AUTOSAR XML (schema 00044)
package /ComponentTypes
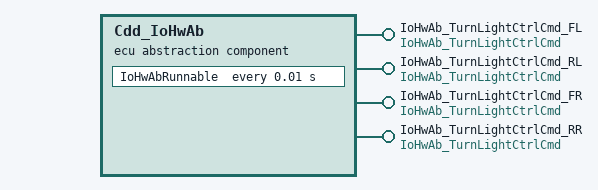
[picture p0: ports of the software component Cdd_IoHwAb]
  ecu abstraction sw component type Cdd_IoHwAb
    4 x provide port, all with server-com-spec{operation=Operation, queue-length=1}, provided-interface=IoHwAb_TurnLightCtrlCmd:
      IoHwAb_TurnLightCtrlCmd_FL
      IoHwAb_TurnLightCtrlCmd_RL
      IoHwAb_TurnLightCtrlCmd_FR
      IoHwAb_TurnLightCtrlCmd_RR
    behavior Cdd_IoHwAb_InternalBehavior
      timing event TMT_IoHwAbRunnable: start-on-event=IoHwAbRunnable, period=0.01
      4 x operation invoked event:
        OIT_Runnable_IoHwAb_TurnLightCtrlCmd_FL_Operation: start-on-event=IoHwAb_TurnLightCtrlCmd_FL_Operation, operation=IoHwAb_TurnLightCtrlCmd_FL.Operation
        OIT_IoHwAb_TurnLightCtrlCmd_FR_Operation_IoHwAb_TurnLightCtrlCmd_FR_Operation: start-on-event=IoHwAb_TurnLightCtrlCmd_FR_Operation, operation=IoHwAb_TurnLightCtrlCmd_FR.Operation
        OIT_IoHwAb_TurnLightCtrlCmd_RL_Operation_IoHwAb_TurnLightCtrlCmd_RL_Operation: start-on-event=IoHwAb_TurnLightCtrlCmd_RL_Operation, operation=IoHwAb_TurnLightCtrlCmd_RL.Operation
        OIT_IoHwAb_TurnLightCtrlCmd_RR_Operation_IoHwAb_TurnLightCtrlCmd_RR_Operation: start-on-event=IoHwAb_TurnLightCtrlCmd_RR_Operation, operation=IoHwAb_TurnLightCtrlCmd_RR.Operation
      5 x runnable:
        IoHwAbRunnable: minimum-start-interval=0.01
        IoHwAb_TurnLightCtrlCmd_FL_Operation
        IoHwAb_TurnLightCtrlCmd_FR_Operation
        IoHwAb_TurnLightCtrlCmd_RL_Operation
        IoHwAb_TurnLightCtrlCmd_RR_Operation
  swc implementation Cdd_IoHwAb_Implementation: behavior=Cdd_IoHwAb_InternalBehavior
